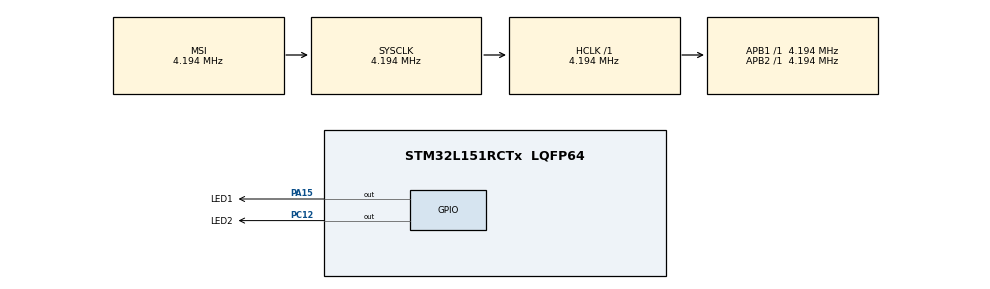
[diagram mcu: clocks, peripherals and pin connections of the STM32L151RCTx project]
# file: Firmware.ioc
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Mcu.Family=STM32L1
Mcu.Name=STM32L151RCTx
Mcu.Package=LQFP64
NVIC.PriorityGroup=NVIC_PRIORITYGROUP_4
PA13.Mode=Serial_Wire
PA13.Signal=SYS_JTMS-SWDIO
PA14.Mode=Serial_Wire
PA14.Signal=SYS_JTCK-SWCLK
PA15.GPIO_Label=LED1
PA15.Signal=GPIO_Output
PC12.GPIO_Label=LED2
PC12.Signal=GPIO_Output
ProjectManager.HeapSize=0x200
ProjectManager.StackSize=0x400
ProjectManager.TargetToolchain=EWARM V8.32
RCC.48MHZClocksFreq_Value=32000000
RCC.AHBFreq_Value=4194000
RCC.APB1Freq_Value=4194000
RCC.APB1TimFreq_Value=4194000
RCC.APB2Freq_Value=4194000
RCC.APB2TimFreq_Value=4194000
RCC.HCLKFreq_Value=4194000
RCC.HSE_VALUE=24000000
RCC.HSI_VALUE=16000000
RCC.MSIClockRange=RCC_MSIRANGE_6
RCC.MSI_VALUE=4194000
RCC.PLLMUL=RCC_PLL_MUL4
RCC.RTCClockSelection=RCC_RTCCLKSOURCE_LSE
RCC.RTCClockSelectionVirtual=RCC_RTCCLKSOURCE_LSE
RCC.SYSCLKFreq_VALUE=4194000
RCC.VCOOutputFreq_Value=64000000
board=custom

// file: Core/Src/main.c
/* USER CODE BEGIN Header */
/**
  ******************************************************************************
  * @file           : main.c
  * @brief          : Main program body
  ******************************************************************************
  * @attention
  *
  * Copyright (c) 2022 STMicroelectronics.
  * All rights reserved.
  *
  * This software is licensed under terms that can be found in the LICENSE file
  * in the root directory of this software component.
  * If no LICENSE file comes with this software, it is provided AS-IS.
  *
  ******************************************************************************
  */
/* USER CODE END Header */
#include "main.h"
#include "gpio.h"

/* USER CODE BEGIN Includes */
#include "onchipflash.h"
#include "user_manage_onflash.h"
/* USER CODE END Includes */

/* USER CODE BEGIN PV */
uint32_t	HaveNewFirmware = 0;
uint32_t	NewFirmwareSize = 0;
uint32_t	JumpAddress;
uint32_t	i = 0;

typedef  void (*pFunction)(void);
pFunction Jump_To_Application;

/* USER CODE END PV */

void SystemClock_Config(void);

int main(void)
{

  /* MCU Configuration--------------------------------------------------------*/

  /* Reset of all peripherals, Initializes the Flash interface and the Systick. */
  HAL_Init();

  /* Configure the system clock */
  SystemClock_Config();

  /* Initialize all configured peripherals */
  MX_GPIO_Init();
  /* USER CODE BEGIN 2 */
    HaveNewFirmware = *(__IO uint32_t*)(ADDR_FLAG_HAVE_NEW_FW);
	NewFirmwareSize = *(__IO uint32_t*)(ADDR_FLAG_HAVE_NEW_FW + 0x04);

	if (HaveNewFirmware == 0xAA)
	{
        HAL_GPIO_WritePin(LED1_GPIO_Port, LED1_Pin, GPIO_PIN_SET);

        Erase_Firmware (ADDR_MAIN_PROGRAM, FIRMWARE_SIZE_PAGE);
		// Copy new firmware to right position
		OnchipFlashCopy(ADDR_UPDATE_PROGRAM, ADDR_MAIN_PROGRAM, NewFirmwareSize);

		//Clear new firmware flag
		OnchipFlashPageErase(ADDR_FLAG_HAVE_NEW_FW);
	}

	JumpAddress = *((__IO uint32_t*)(ADDR_MAIN_PROGRAM + 0x04));

	Jump_To_Application = (pFunction) JumpAddress;

	// Initialize user application's Stack Pointer
	__set_MSP(*(__IO uint32_t*) ADDR_MAIN_PROGRAM);

	Jump_To_Application();
  /* USER CODE END 2 */

  /* Infinite loop */
  while (1)
  {

  }
}

void SystemClock_Config(void)
{
  RCC_OscInitTypeDef RCC_OscInitStruct = {0};
  RCC_ClkInitTypeDef RCC_ClkInitStruct = {0};

  /** Configure the main internal regulator output voltage
  */
  __HAL_PWR_VOLTAGESCALING_CONFIG(PWR_REGULATOR_VOLTAGE_SCALE1);

  /** Initializes the RCC Oscillators according to the specified parameters
  * in the RCC_OscInitTypeDef structure.
  */
  RCC_OscInitStruct.OscillatorType = RCC_OSCILLATORTYPE_MSI;
  RCC_OscInitStruct.MSIState = RCC_MSI_ON;
  RCC_OscInitStruct.MSICalibrationValue = 0;
  RCC_OscInitStruct.MSIClockRange = RCC_MSIRANGE_6;
  RCC_OscInitStruct.PLL.PLLState = RCC_PLL_NONE;
  if (HAL_RCC_OscConfig(&RCC_OscInitStruct) != HAL_OK)
  {
    Error_Handler();
  }

  /** Initializes the CPU, AHB and APB buses clocks
  */
  RCC_ClkInitStruct.ClockType = RCC_CLOCKTYPE_HCLK|RCC_CLOCKTYPE_SYSCLK
                              |RCC_CLOCKTYPE_PCLK1|RCC_CLOCKTYPE_PCLK2;
  RCC_ClkInitStruct.SYSCLKSource = RCC_SYSCLKSOURCE_MSI;
  RCC_ClkInitStruct.AHBCLKDivider = RCC_SYSCLK_DIV1;
  RCC_ClkInitStruct.APB1CLKDivider = RCC_HCLK_DIV1;
  RCC_ClkInitStruct.APB2CLKDivider = RCC_HCLK_DIV1;

  if (HAL_RCC_ClockConfig(&RCC_ClkInitStruct, FLASH_LATENCY_0) != HAL_OK)
  {
    Error_Handler();
  }
}

void Error_Handler(void)
{
  __disable_irq();
  while (1)
  {
  }
}
